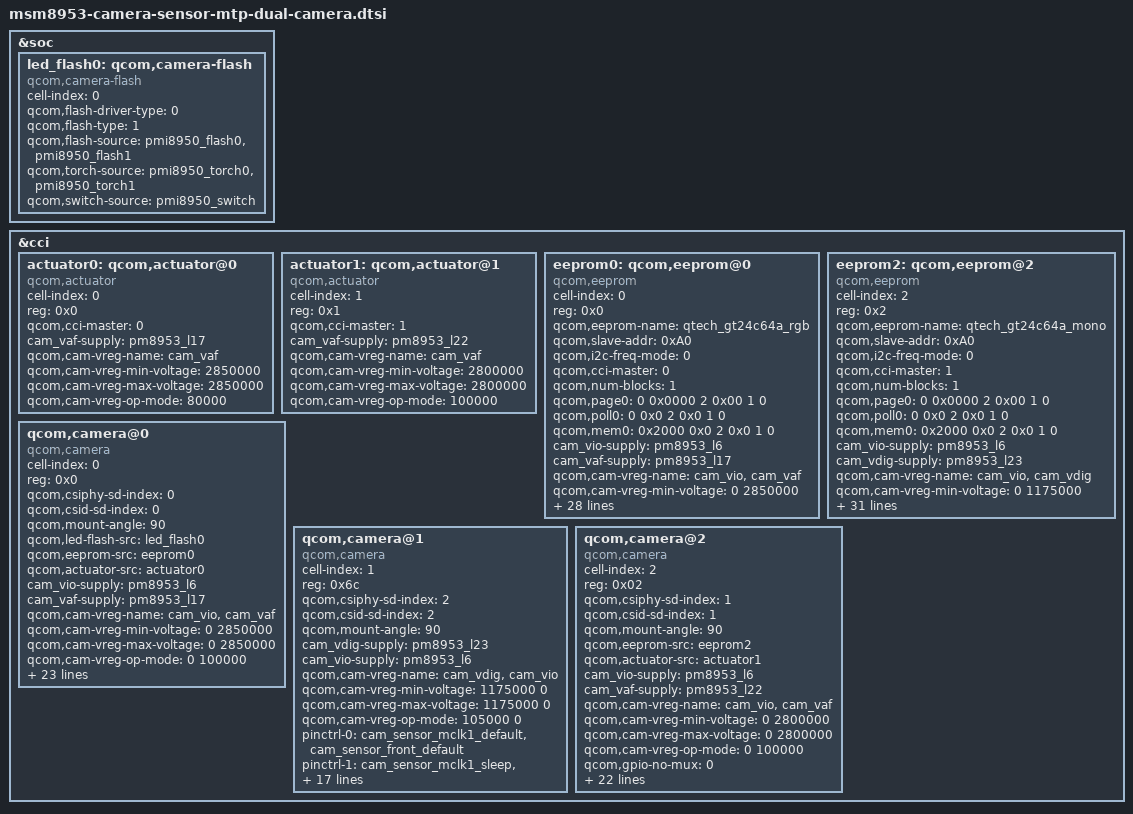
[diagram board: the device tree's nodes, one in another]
/*
 * Copyright (c) 2015-2016, The Linux Foundation. All rights reserved.
 *
 * This program is free software; you can redistribute it and/or modify
 * it under the terms of the GNU General Public License version 2 and
 * only version 2 as published by the Free Software Foundation.
 *
 * This program is distributed in the hope that it will be useful,
 * but WITHOUT ANY WARRANTY; without even the implied warranty of
 * MERCHANTABILITY or FITNESS FOR A PARTICULAR PURPOSE.  See the
 * GNU General Public License for more details.
 */

&soc {
	led_flash0: qcom,camera-flash {
		cell-index = <0>;
		compatible = "qcom,camera-flash";
		qcom,flash-driver-type = <0>;
		qcom,flash-type = <1>;
		qcom,flash-source = <&pmi8950_flash0 &pmi8950_flash1>;
		qcom,torch-source = <&pmi8950_torch0 &pmi8950_torch1>;
		qcom,switch-source = <&pmi8950_switch>;
	};
};

&cci {
	actuator0: qcom,actuator@0 {
		cell-index = <0>;
		reg = <0x0>;
		compatible = "qcom,actuator";
		qcom,cci-master = <0>;
		cam_vaf-supply = <&pm8953_l17>;
		qcom,cam-vreg-name = "cam_vaf";
		qcom,cam-vreg-min-voltage = <2850000>;
		qcom,cam-vreg-max-voltage = <2850000>;
		qcom,cam-vreg-op-mode = <80000>;
	};
	actuator1: qcom,actuator@1 {
		cell-index = <1>;
		reg = <0x1>;
		compatible = "qcom,actuator";
		qcom,cci-master = <1>;
		cam_vaf-supply = <&pm8953_l22>;
		qcom,cam-vreg-name = "cam_vaf";
		qcom,cam-vreg-min-voltage = <2800000>;
		qcom,cam-vreg-max-voltage = <2800000>;
		qcom,cam-vreg-op-mode = <100000>;
	};

	eeprom0: qcom,eeprom@0 {
		cell-index = <0>;
		reg = <0x0>;
		qcom,eeprom-name = "qtech_gt24c64a_rgb";
		compatible = "qcom,eeprom";
		qcom,slave-addr = <0xA0>;
		qcom,i2c-freq-mode= <0>;
		qcom,cci-master = <0>;
		qcom,num-blocks = <1>;
		qcom,page0 = <0 0x0000 2 0x00 1 0>;
		qcom,poll0 = <0 0x0 2 0x0 1 0>;
		qcom,mem0 = <0x2000 0x0 2 0x0 1 0>;
		cam_vio-supply = <&pm8953_l6>;
		cam_vaf-supply = <&pm8953_l17>;
		qcom,cam-vreg-name = "cam_vio", "cam_vaf";
		qcom,cam-vreg-min-voltage = <0 2850000>;
		qcom,cam-vreg-max-voltage = <0 2850000>;
		qcom,cam-vreg-op-mode = <0 80000>;
		pinctrl-names = "cam_default", "cam_suspend";
		pinctrl-0 = <&cam_sensor_mclk0_default
				&cam_sensor_rear_default>;
		pinctrl-1 = <&cam_sensor_mclk0_sleep
				&cam_sensor_rear_sleep>;
		gpios = <&tlmm 26 0>,
			<&tlmm 35 0>,
			<&tlmm 44 0>,
			<&tlmm 130 0>,
			<&tlmm 9 0>,
			<&tlmm 36 0>,
			<&pm8953_gpios 4 0>;
		qcom,gpio-vana = <1>;
		qcom,gpio-vio = <2>;
		qcom,gpio-standby = <3>;
		qcom,gpio-reset = <4>;
		qcom,gpio-vdig = <5>;
		qcom,gpio-custom1 = <6>;
		qcom,gpio-req-tbl-num = <0 1 2 3 4 5 6>;
		qcom,gpio-req-tbl-flags = <1 0 0 0 0 0 0>;
		qcom,gpio-req-tbl-label = "CAMIF_MCLK0",
			"CAM_VANA0",
			"CAM_VIO0",
			"CAM_STANDBY0",
			"CAM_RESET0",
			"CAM_VDIG0",
			"CAM_CUSTOM1";
		qcom,cam-power-seq-type = "sensor_gpio", "sensor_vreg", "sensor_gpio";
		qcom,cam-power-seq-val =  "sensor_gpio_vio", "cam_vio", "sensor_gpio_vio";
		qcom,cam-power-seq-cfg-val = <0 1 1>;
		qcom,cam-power-seq-delay = <1 1 1>;
		status = "ok";
		clocks = <&clock_gcc clk_mclk0_clk_src>,
			<&clock_gcc clk_gcc_camss_mclk0_clk>;
		clock-names = "cam_src_clk", "cam_clk";
		qcom,clock-rates = <19200000 0>;
	};
	eeprom2: qcom,eeprom@2 {
		cell-index = <2>;
		reg = <0x2>;
		qcom,eeprom-name = "qtech_gt24c64a_mono";
		compatible = "qcom,eeprom";
		qcom,slave-addr = <0xA0>;
		qcom,i2c-freq-mode= <0>;
		qcom,cci-master = <1>;
		qcom,num-blocks = <1>;
		qcom,page0 = <0 0x0000 2 0x00 1 0>;
		qcom,poll0 = <0 0x0 2 0x0 1 0>;
		qcom,mem0 = <0x2000 0x0 2 0x0 1 0>;
		cam_vio-supply = <&pm8953_l6>;
		cam_vdig-supply = <&pm8953_l23>;
		qcom,cam-vreg-name = "cam_vio", "cam_vdig";
		qcom,cam-vreg-min-voltage = <0 1175000>;
		qcom,cam-vreg-max-voltage = <0 1175000>;
		qcom,cam-vreg-op-mode = <0 105000>;
		pinctrl-names = "cam_default", "cam_suspend";
		pinctrl-0 = <&cam_sensor_mclk2_default
						&cam_sensor_front_default
						&cam_sensor_front1_default>;
		pinctrl-1 = <&cam_sensor_mclk2_sleep
						&cam_sensor_front_sleep
						&cam_sensor_front1_sleep>;
		gpios = <&tlmm 59 0>,
			<&pm8953_gpios 5 0>,
			<&tlmm 8 0>,
			<&tlmm 89 0>,
			<&tlmm 41 0>;
		qcom,gpio-vio = <0>;
		qcom,gpio-custom2 = <1>;
		qcom,gpio-custom3 = <2>;
		qcom,gpio-vana = <3>;
		qcom,gpio-vdig = <4>;
		qcom,gpio-req-tbl-num = <0 1 2 3 4>;
		qcom,gpio-req-tbl-flags = <0 0 0 0 0>;
		qcom,gpio-req-tbl-label = "CAM_VIO2", "CAM_VIO1", "CAM_VANA1", "CAM_VANA2", "CAM_VDIG2";
		qcom,cam-power-seq-type = "sensor_vreg", "sensor_gpio", "sensor_gpio",
						"sensor_vreg", "sensor_gpio", "sensor_gpio", "sensor_gpio";
		qcom,cam-power-seq-val =  "cam_vio", "sensor_gpio_vio", "sensor_gpio_vana",
						"cam_vdig", "sensor_gpio_vio", "sensor_gpio_vana", "sensor_gpio_vdig";
		qcom,cam-power-seq-cfg-val = <1 1 1 1 1 1 1>;
		qcom,cam-power-seq-delay = <1 1 1 1 1 1 1>;
		status = "ok";
		clocks = <&clock_gcc clk_mclk2_clk_src>,
			<&clock_gcc clk_gcc_camss_mclk2_clk>;
		clock-names = "cam_src_clk", "cam_clk";
		qcom,clock-rates = <24000000 0>;
	};

	qcom,camera@0 {
		cell-index = <0>;
		compatible = "qcom,camera";
		reg = <0x0>;
		qcom,csiphy-sd-index = <0>;
		qcom,csid-sd-index = <0>;
		qcom,mount-angle = <90>;
		qcom,led-flash-src = <&led_flash0>;
		qcom,eeprom-src = <&eeprom0>;
		qcom,actuator-src = <&actuator0>;
		cam_vio-supply = <&pm8953_l6>;
		cam_vaf-supply = <&pm8953_l17>;
		qcom,cam-vreg-name = "cam_vio", "cam_vaf";
		qcom,cam-vreg-min-voltage = <0 2850000>;
		qcom,cam-vreg-max-voltage = <0 2850000>;
		qcom,cam-vreg-op-mode = <0 100000>;
		pinctrl-names = "cam_default", "cam_suspend";
		pinctrl-0 = <&cam_sensor_mclk0_default
				&cam_sensor_rear_default
				/*&cam_sensor_rear_vana*/>;
		pinctrl-1 = <&cam_sensor_mclk0_sleep &cam_sensor_rear_sleep
				/*&cam_sensor_rear_vana_sleep*/>;
		gpios = <&tlmm 26 0>,
			<&tlmm 35 0>,
			<&tlmm 44 0>,
			<&tlmm 130 0>,
			<&tlmm 9 0>,
			<&tlmm 36 0>,
			<&pm8953_gpios 4 0>;
		qcom,gpio-vana = <1>;
		qcom,gpio-vio = <2>;
		qcom,gpio-standby = <3>;
		qcom,gpio-reset = <4>;
		qcom,gpio-vdig = <5>;
		qcom,gpio-custom1 = <6>;
		qcom,gpio-req-tbl-num = <0 1 2 3 4 5 6>;
		qcom,gpio-req-tbl-flags = <1 0 0 0 0 0 0>;
		qcom,gpio-req-tbl-label = "CAMIF_MCLK0",
			"CAM_VANA0",
			"CAM_VIO0",
			"CAM_STANDBY0",
			"CAM_RESET0",
			"CAM_VDIG0",
			"CAM_CUSTOM1";
		qcom,sensor-position = <0>;
		qcom,sensor-mode = <0>;
		qcom,cci-master = <0>;
		status = "ok";
		clocks = <&clock_gcc clk_mclk0_clk_src>,
				<&clock_gcc clk_gcc_camss_mclk0_clk>;
		clock-names = "cam_src_clk", "cam_clk";
		qcom,clock-rates = <24000000 0>;
	};

	qcom,camera@1 {
		cell-index = <1>;
		compatible = "qcom,camera";
		reg = <0x6c>;
		qcom,csiphy-sd-index = <2>;
		qcom,csid-sd-index = <2>;
		qcom,mount-angle = <90>;
		//qcom,eeprom-src = <&eeprom1>;
		cam_vdig-supply = <&pm8953_l23>;
		cam_vio-supply = <&pm8953_l6>;
		qcom,cam-vreg-name = "cam_vdig", "cam_vio";
		qcom,cam-vreg-min-voltage = <1175000 0>;
		qcom,cam-vreg-max-voltage = <1175000 0>;
		qcom,cam-vreg-op-mode = <105000 0>;
		pinctrl-names = "cam_default", "cam_suspend";
		pinctrl-0 = <&cam_sensor_mclk1_default
				&cam_sensor_front_default>;
		pinctrl-1 = <&cam_sensor_mclk1_sleep
				&cam_sensor_front_sleep>;
		gpios = <&tlmm 27 0>,
			<&tlmm 8 0>,
			<&pm8953_gpios 5 0>,
			<&pm8953_gpios 6 0>,
			<&tlmm 59 0>;
		qcom,gpio-vana = <1>;
		qcom,gpio-vio = <2>;
		qcom,gpio-reset = <3>;
		qcom,gpio-custom1 = <4>;
		qcom,gpio-req-tbl-num = <0 1 2 3 4>;
		qcom,gpio-req-tbl-flags = <1 0 0 0 0>;
		qcom,gpio-req-tbl-label = "CAMIF_MCLK1",
			"CAM_VANA1",
			"CAM_VIO1",
			"CAM_RESET1",
			"CAM_CUSTOM1";
		qcom,sensor-position = <1>;
		qcom,sensor-mode = <1>;
		qcom,cci-master = <1>;
		status = "ok";
		clocks = <&clock_gcc clk_mclk1_clk_src>,
				<&clock_gcc clk_gcc_camss_mclk1_clk>;
		clock-names = "cam_src_clk", "cam_clk";
		qcom,clock-rates = <24000000 0>;
	};

	qcom,camera@2 {
		cell-index = <2>;
		compatible = "qcom,camera";
		reg = <0x02>;
		qcom,csiphy-sd-index = <1>;
		qcom,csid-sd-index = <1>;
		qcom,mount-angle = <90>;
		qcom,eeprom-src = <&eeprom2>;
		qcom,actuator-src = <&actuator1>;
		cam_vio-supply = <&pm8953_l6>;
		cam_vaf-supply = <&pm8953_l22>;
		qcom,cam-vreg-name = "cam_vio",
					"cam_vaf";
		qcom,cam-vreg-min-voltage = <0 2800000>;
		qcom,cam-vreg-max-voltage = <0 2800000>;
		qcom,cam-vreg-op-mode = <0 100000>;
		qcom,gpio-no-mux = <0>;
		pinctrl-names = "cam_default", "cam_suspend";
		pinctrl-0 = <&cam_sensor_mclk2_default
				&cam_sensor_front1_default>;
		pinctrl-1 = <&cam_sensor_mclk2_sleep
				&cam_sensor_front1_sleep>;
		gpios = <&tlmm 28 0>,
			<&tlmm 41 0>,
			<&tlmm 89 0>,
			<&tlmm 59 0>,
			<&tlmm 40 0>,
			<&tlmm 39 0>;
		qcom,gpio-vdig = <1>;
		qcom,gpio-vana = <2>;
		qcom,gpio-vio = <3>;
		qcom,gpio-reset = <4>;
		qcom,gpio-standby = <5>;
		qcom,gpio-req-tbl-num = <0 1 2 3 4 5>;
		qcom,gpio-req-tbl-flags = <1 0 0 0 0 0>;
		qcom,gpio-req-tbl-label = "CAMIF_MCLK2",
						"CAM_VDIG2",
						"CAM_VANA2",
						"CAM_VIO2",
						"CAM_RESET2",
						"CAM_STANDBY2";
		qcom,sensor-position = <2>;
		qcom,sensor-mode = <0>;
		qcom,cci-master = <1>;
		status = "ok";
		clocks = <&clock_gcc clk_mclk2_clk_src>,
			<&clock_gcc clk_gcc_camss_mclk2_clk>;
		clock-names = "cam_src_clk", "cam_clk";
		qcom,clock-rates = <24000000 0>;
	};
};
